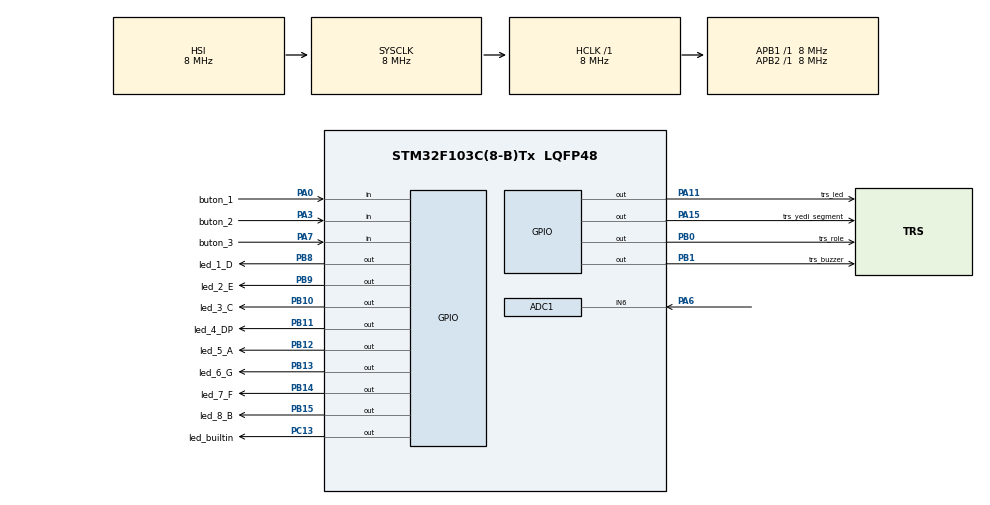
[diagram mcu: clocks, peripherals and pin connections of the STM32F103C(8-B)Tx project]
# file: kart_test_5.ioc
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ADC1.Channel-4\#ChannelRegularConversion=ADC_CHANNEL_6
ADC1.NbrOfConversionFlag=1
ADC1.Rank-4\#ChannelRegularConversion=1
ADC1.SamplingTime-4\#ChannelRegularConversion=ADC_SAMPLETIME_1CYCLE_5
ADC1.master=1
Mcu.Family=STM32F1
Mcu.Name=STM32F103C(8-B)Tx
Mcu.Package=LQFP48
NVIC.PriorityGroup=NVIC_PRIORITYGROUP_4
PA0-WKUP.GPIO_Label=buton_1
PA0-WKUP.Signal=GPIO_Input
PA11.GPIO_Label=trs_led
PA11.Signal=GPIO_Output
PA15.GPIO_Label=trs_yedi_segment
PA15.Signal=GPIO_Output
PA3.GPIO_Label=buton_2
PA3.Signal=GPIO_Input
PA6.Signal=ADCx_IN6
PA7.GPIO_Label=buton_3
PA7.Signal=GPIO_Input
PB0.GPIO_Label=trs_role
PB0.Signal=GPIO_Output
PB1.GPIO_Label=trs_buzzer
PB1.Signal=GPIO_Output
PB10.GPIO_Label=led_3_C
PB10.PinState=GPIO_PIN_RESET
PB10.Signal=GPIO_Output
PB11.GPIO_Label=led_4_DP
PB11.PinState=GPIO_PIN_RESET
PB11.Signal=GPIO_Output
PB12.GPIO_Label=led_5_A
PB12.PinState=GPIO_PIN_RESET
PB12.Signal=GPIO_Output
PB13.GPIO_Label=led_6_G
PB13.PinState=GPIO_PIN_RESET
PB13.Signal=GPIO_Output
PB14.GPIO_Label=led_7_F
PB14.PinState=GPIO_PIN_RESET
PB14.Signal=GPIO_Output
PB15.GPIO_Label=led_8_B
PB15.PinState=GPIO_PIN_RESET
PB15.Signal=GPIO_Output
PB8.GPIO_Label=led_1_D
PB8.PinState=GPIO_PIN_RESET
PB8.Signal=GPIO_Output
PB9.GPIO_Label=led_2_E
PB9.PinState=GPIO_PIN_RESET
PB9.Signal=GPIO_Output
PC13-TAMPER-RTC.GPIO_Label=led_builtin
PC13-TAMPER-RTC.PinState=GPIO_PIN_RESET
PC13-TAMPER-RTC.Signal=GPIO_Output
ProjectManager.HeapSize=0x200
ProjectManager.StackSize=0x400
ProjectManager.TargetToolchain=STM32CubeIDE
RCC.AHBFreq_Value=8000000
RCC.APB1Freq_Value=8000000
RCC.APB1TimFreq_Value=8000000
RCC.APB2Freq_Value=8000000
RCC.APB2TimFreq_Value=8000000
RCC.HCLKFreq_Value=8000000
RCC.PLLMUL=RCC_PLL_MUL4
RCC.SYSCLKFreq_VALUE=8000000
RCC.USBFreq_Value=16000000
SH.ADCx_IN6.0=ADC1_IN6,IN6
VP_SYS_VS_ND.Mode=No_Debug
board=custom

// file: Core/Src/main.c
/* USER CODE BEGIN Header */
/**
  ******************************************************************************
  * @file           : main.c
  * @brief          : Main program body
  ******************************************************************************
  * @attention
  *
  * Copyright (c) 2025 STMicroelectronics.
  * All rights reserved.
  *
  * This software is licensed under terms that can be found in the LICENSE file
  * in the root directory of this software component.
  * If no LICENSE file comes with this software, it is provided AS-IS.
  *
  ******************************************************************************
  */
/* USER CODE END Header */
#include "main.h"
#include <led_display_role_buzzer_test.h>
#include <buton_test.h>
#include <yedisegment_ekran_yazdirma.h>
#include <adc_test.h>

ADC_HandleTypeDef hadc1;

/* USER CODE BEGIN PV */
uint16_t sayac=0;
/* USER CODE END PV */

void SystemClock_Config(void);
static void MX_GPIO_Init(void);
static void MX_ADC1_Init(void);

int main(void)
{

  /* MCU Configuration--------------------------------------------------------*/

  /* Reset of all peripherals, Initializes the Flash interface and the Systick. */
  HAL_Init();

  /* Configure the system clock */
  SystemClock_Config();

  /* Initialize all configured peripherals */
  MX_GPIO_Init();
  MX_ADC1_Init();
  /* USER CODE BEGIN 2 */
  HAL_GPIO_WritePin(trs_yedi_segment_GPIO_Port, trs_led_Pin, GPIO_PIN_SET);
  //HAL_GPIO_WritePin(trs_buzzer_GPIO_Port, trs_buzzer_Pin, GPIO_PIN_SET);
  /* USER CODE END 2 */

  /* Infinite loop */
  while (1)
  {

    /* USER CODE BEGIN 3 */
	role_testi();
	buzzer_testi();
	led_display_testi();
	buton_test();

	for(sayac=0;sayac<10;sayac++)
	{

		yedi_segment_yazdir(sayac);
		HAL_Delay(750);
	}

	adc_test();

  }
  /* USER CODE END 3 */
}

void SystemClock_Config(void)
{
  RCC_OscInitTypeDef RCC_OscInitStruct = {0};
  RCC_ClkInitTypeDef RCC_ClkInitStruct = {0};
  RCC_PeriphCLKInitTypeDef PeriphClkInit = {0};

  /** Initializes the RCC Oscillators according to the specified parameters
  * in the RCC_OscInitTypeDef structure.
  */
  RCC_OscInitStruct.OscillatorType = RCC_OSCILLATORTYPE_HSI;
  RCC_OscInitStruct.HSIState = RCC_HSI_ON;
  RCC_OscInitStruct.HSICalibrationValue = RCC_HSICALIBRATION_DEFAULT;
  RCC_OscInitStruct.PLL.PLLState = RCC_PLL_NONE;
  if (HAL_RCC_OscConfig(&RCC_OscInitStruct) != HAL_OK)
  {
    Error_Handler();
  }

  /** Initializes the CPU, AHB and APB buses clocks
  */
  RCC_ClkInitStruct.ClockType = RCC_CLOCKTYPE_HCLK|RCC_CLOCKTYPE_SYSCLK
                              |RCC_CLOCKTYPE_PCLK1|RCC_CLOCKTYPE_PCLK2;
  RCC_ClkInitStruct.SYSCLKSource = RCC_SYSCLKSOURCE_HSI;
  RCC_ClkInitStruct.AHBCLKDivider = RCC_SYSCLK_DIV1;
  RCC_ClkInitStruct.APB1CLKDivider = RCC_HCLK_DIV1;
  RCC_ClkInitStruct.APB2CLKDivider = RCC_HCLK_DIV1;

  if (HAL_RCC_ClockConfig(&RCC_ClkInitStruct, FLASH_LATENCY_0) != HAL_OK)
  {
    Error_Handler();
  }
  PeriphClkInit.PeriphClockSelection = RCC_PERIPHCLK_ADC;
  PeriphClkInit.AdcClockSelection = RCC_ADCPCLK2_DIV2;
  if (HAL_RCCEx_PeriphCLKConfig(&PeriphClkInit) != HAL_OK)
  {
    Error_Handler();
  }
}

static void MX_ADC1_Init(void)
{

  ADC_ChannelConfTypeDef sConfig = {0};

  /** Common config
  */
  hadc1.Instance = ADC1;
  hadc1.Init.ScanConvMode = ADC_SCAN_DISABLE;
  hadc1.Init.ContinuousConvMode = DISABLE;
  hadc1.Init.DiscontinuousConvMode = DISABLE;
  hadc1.Init.ExternalTrigConv = ADC_SOFTWARE_START;
  hadc1.Init.DataAlign = ADC_DATAALIGN_RIGHT;
  hadc1.Init.NbrOfConversion = 1;
  if (HAL_ADC_Init(&hadc1) != HAL_OK)
  {
    Error_Handler();
  }

  /** Configure Regular Channel
  */
  sConfig.Channel = ADC_CHANNEL_6;
  sConfig.Rank = ADC_REGULAR_RANK_1;
  sConfig.SamplingTime = ADC_SAMPLETIME_1CYCLE_5;
  if (HAL_ADC_ConfigChannel(&hadc1, &sConfig) != HAL_OK)
  {
    Error_Handler();
  }

}

static void MX_GPIO_Init(void)
{
  GPIO_InitTypeDef GPIO_InitStruct = {0};

  /* GPIO Ports Clock Enable */
  __HAL_RCC_GPIOC_CLK_ENABLE();
  __HAL_RCC_GPIOA_CLK_ENABLE();
  __HAL_RCC_GPIOB_CLK_ENABLE();

  /*Configure GPIO pin Output Level */
  HAL_GPIO_WritePin(led_builtin_GPIO_Port, led_builtin_Pin, GPIO_PIN_RESET);

  /*Configure GPIO pin Output Level */
  HAL_GPIO_WritePin(GPIOB, trs_role_Pin|trs_buzzer_Pin|led_3_C_Pin|led_4_DP_Pin
                          |led_5_A_Pin|led_6_G_Pin|led_7_F_Pin|led_8_B_Pin
                          |led_1_D_Pin|led_2_E_Pin, GPIO_PIN_RESET);

  /*Configure GPIO pin Output Level */
  HAL_GPIO_WritePin(GPIOA, trs_led_Pin|trs_yedi_segment_Pin, GPIO_PIN_RESET);

  /*Configure GPIO pin : led_builtin_Pin */
  GPIO_InitStruct.Pin = led_builtin_Pin;
  GPIO_InitStruct.Mode = GPIO_MODE_OUTPUT_PP;
  GPIO_InitStruct.Pull = GPIO_NOPULL;
  GPIO_InitStruct.Speed = GPIO_SPEED_FREQ_LOW;
  HAL_GPIO_Init(led_builtin_GPIO_Port, &GPIO_InitStruct);

  /*Configure GPIO pins : buton_1_Pin buton_2_Pin buton_3_Pin */
  GPIO_InitStruct.Pin = buton_1_Pin|buton_2_Pin|buton_3_Pin;
  GPIO_InitStruct.Mode = GPIO_MODE_INPUT;
  GPIO_InitStruct.Pull = GPIO_NOPULL;
  HAL_GPIO_Init(GPIOA, &GPIO_InitStruct);

  /*Configure GPIO pins : trs_role_Pin trs_buzzer_Pin led_3_C_Pin led_4_DP_Pin
                           led_5_A_Pin led_6_G_Pin led_7_F_Pin led_8_B_Pin
                           led_1_D_Pin led_2_E_Pin */
  GPIO_InitStruct.Pin = trs_role_Pin|trs_buzzer_Pin|led_3_C_Pin|led_4_DP_Pin
                          |led_5_A_Pin|led_6_G_Pin|led_7_F_Pin|led_8_B_Pin
                          |led_1_D_Pin|led_2_E_Pin;
  GPIO_InitStruct.Mode = GPIO_MODE_OUTPUT_PP;
  GPIO_InitStruct.Pull = GPIO_NOPULL;
  GPIO_InitStruct.Speed = GPIO_SPEED_FREQ_LOW;
  HAL_GPIO_Init(GPIOB, &GPIO_InitStruct);

  /*Configure GPIO pins : trs_led_Pin trs_yedi_segment_Pin */
  GPIO_InitStruct.Pin = trs_led_Pin|trs_yedi_segment_Pin;
  GPIO_InitStruct.Mode = GPIO_MODE_OUTPUT_PP;
  GPIO_InitStruct.Pull = GPIO_NOPULL;
  GPIO_InitStruct.Speed = GPIO_SPEED_FREQ_LOW;
  HAL_GPIO_Init(GPIOA, &GPIO_InitStruct);

}

void Error_Handler(void)
{
  __disable_irq();
  while (1)
  {
  }
}
